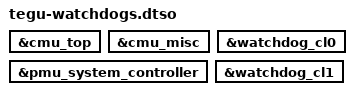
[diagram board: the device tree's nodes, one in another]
// SPDX-License-Identifier: MIT
/dts-v1/;
/plugin/;

/* Take over both cluster watchdogs left running by ABL. */
&cmu_top { status = "okay"; };
&cmu_misc { status = "okay"; };
&pmu_system_controller { status = "okay"; };
&watchdog_cl0 { status = "okay"; };
&watchdog_cl1 { status = "okay"; };
